# DP32G030 register map
File version: 1.0
CPU: CM0 r0p0, little endian, no MPU, no FPU, 4 interrupt priority bits
Registers are 32-bit, read-write, reset 0x0 unless marked. A register's access mark holds for its fields unless they carry their own. Offsets are from the block's base; [hi:lo] are bit positions.

## IIC0 — IIC0 unit
Base 0x400B9000
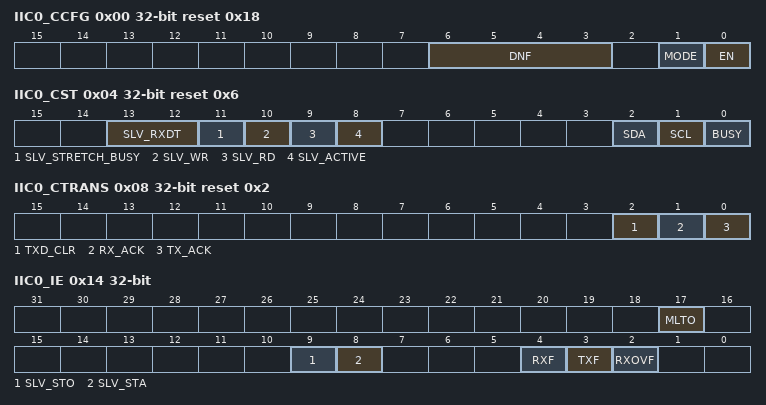
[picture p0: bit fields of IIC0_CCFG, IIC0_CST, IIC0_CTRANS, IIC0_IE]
0x00 IIC0_CCFG reset 0x18 — General Configuration Register
  [6:3] DNF — Receive SDA, SCL Digital Noise Filter 0000: Filter not enabled 0001: Filter enable and filter capacity up to 1 system clock ...... 1111: Filter enable and filter capacity up to 15 system clocks
  [1] MODE — Mode Control 0: slave mode 1: master mode
  [0] EN — IIC Bus Enable 0: not enabled 1: Enabling
0x04 IIC0_CST ro reset 0x6 — General Status Register
  [13:12] SLV_RXDT — The type of data received by the Slave. Valid only in Slave mode. 00: RXDATA is empty. 01: The address is received. 10: Data is received. 11: Master code is received. valid only when MCDE=1.
  [11] SLV_STRETCH_BUSY — Slave clock stretching busy state. Valid only in slave mode. 0: Without clock stretching. 1: With clock stretching.
  [10] SLV_WR — Slave write status. Valid only in slave mode. 1: Valid after the slave receives a write request from the master. 0: The slave is cleared automatically after receiving a read request from the master or STOP.
  [9] SLV_RD — Slave read state. Valid only in slave mode. 1: Valid after the slave receives a read request from the master. 0: The slave is cleared automatically after receiving a write request from the master or STOP.
  [8] SLV_ACTIVE — Slave active state. Valid only in slave mode. 0: slave device is inactive 1: The slave device is active. This bit is active after a successful address match; it is automatically cleared after receiving a STOP, or an unsuccessful address match after Start_repeat.
  [2] SDA — IIC SDA Status. Not affected by IIC bus enable 0: IIC SDA is low 1: IIC SDA is high
  [1] SCL — IIC SCL Status. Not affected by IIC bus enable 0: IIC SCL is low 1: IIC SCL is high
  [0] BUSY — Bus Busy Status. This bit is not controlled by the IIC_CCFG.EN bit and still detects the bus busy state when EN is not enabled 0: Bus not busy 1: Bus busy, IIC bus active from START to STOP
0x08 IIC0_CTRANS access per field reset 0x2 — general transfer register
  [2] TXD_CLR wo write-clears — Transmit data register is cleared. Hardware clears it automatically. 0: Not cleared. 1: Clear the IF.TXE bit.
  [1] RX_ACK ro — When acting as a sender, received ACK/NACK. hardware set, IF.TXF is valid to query this bit; received Start_repeat or STOP will set this bit 1. 0: ACK received 1: NACK received
  [0] TX_ACK rw — Sends ACK/NACK when acting as receiver. 0: Sends ACK. 1: Send NACK. Note: In the following cases, ACK/NACK is not determined by this bit: A. The hardware automatically sends an ACK/NACK when the slave receives the address. B. slave MCDE is valid, hardware automatically returns NACK when master code is received. C. The hardware automatically sends a NACK when the slave receives an overflow.
0x0C IIC0_RXDATA ro — Receive Data Register
  [7:0] RXDATA — Receive data register.IF.RXNE is 1, indicating that valid data exists in this register. Note: This register is updated at the moment of completion of data reception (not including ACK/NACK transmission). See the RXF bit description for slave receive address byte conditions.
0x10 IIC0_TXDATA — send data register
  [7:0] TXDATA — Transmit Data Register.IF.TXE is 0, indicating that there is data to be sent in this register.
0x14 IIC0_IE — interrupt enable register
  [17] MLTO — Master SCL LOW Timeout interrupt enable. 0: Not enabled. 1: Enable.
  [9] SLV_STO — Slave detects STOP interrupt enable. 0: Not enabled. 1: Enable.
  [8] SLV_STA — Slave detects START interrupt enable. 0: Not enabled. 1: Enable.
  [4] RXF — End of receive data interrupt enable. 0: Not enabled. 1: Enable.
  [3] TXF — End-of-send data interrupt enable. 0: Not enabled. 1: Enable.
  [2] RXOVF — Receive data register overflow interrupt enable. 0: Not enabled. 1: Enable.
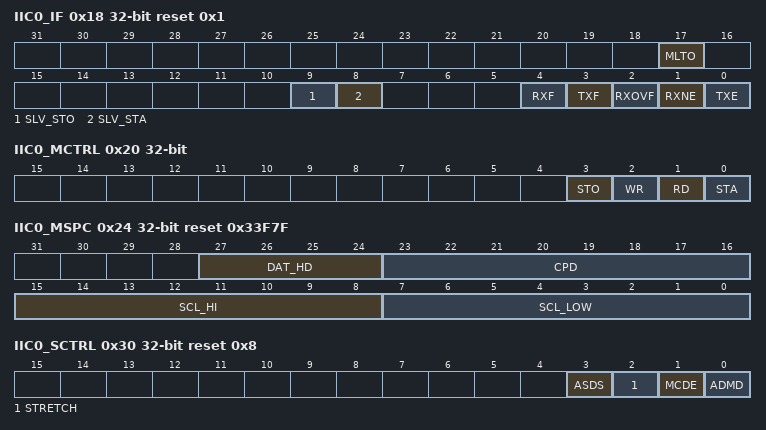
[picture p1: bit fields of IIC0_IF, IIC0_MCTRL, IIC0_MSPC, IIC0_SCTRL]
0x18 IIC0_IF access per field reset 0x1 — Interrupt Flag Register
  [17] MLTO rw write-1-clears — Master SCL LOW timeout. Write 1 clear. Valid only in master mode. 0: No timeout. 1: Timeout. the SCL LOW time exceeds 1024 SCL LOW times set by the MSPC registers.
  [9] SLV_STO rw write-1-clears — Slave detected STOP.write1 clear. Valid only in slave mode. 0: slave did not detect STOP. 1: slave detected STOP.
  [8] SLV_STA rw write-1-clears — Slave detects START. write 1 clear. Valid only in slave mode. 0: slave does not detect START. 1: slave detects START.
  [4] RXF rw write-1-clears — End of reception. Write 1 Clear, contains ACK/NACK time. 0: Receiving is not finished. 1: End of reception. Note: The slave receives the situation description: 1. In 7-bit address mode of Slave device, the slave address byte (inclusive) is used as the address of the slave device. (R/W bits) Receipt is complete and this interrupt is generated if the address matches. 2. In 10-bit address mode of Slave device, when the second byte of slave address (ADDR[7:0]) is received, this interrupt will be generated if the 10-bit address matches; the first byte of the slave address following repeat START, this interrupt will be generated if the address of 8 or9 bits matches; the first byte following repeat START will not generate this interrupt even if ADDR[9:8] matches after the first byte of the slave address has been received. After the first byte following START is received, even if ADDR[9:8] matches, this interrupt will not be generated. 3. Slave mode, SCTRL.MCDE=1, receive master code This interrupt is generated when
  [3] TXF rw write-1-clears — End of transmission. Write 1 Clear, contains ACK/NACK time. 0: Sending is not finished, or not sent. 1: End of sending.
  [2] RXOVF rw write-1-clears — Receive data register overflow. Software Write 1 Clear.(Updated point in time, not including ACK/NACK transmissions) 0: No overflow. 1: When RXDATA is non-null and a new byte is received, an overflow occurs. When the overflow occurs, the new data is lost. Note: For slave mode, if the STRETCH bit is valid, when the receive data register is non-empty and a new byte is received, the slave device pulls down the SCL signal until the old data in RXDATA is read away, and then stores the new data in RXDATA, this case will not generate an overflow.
  [1] RXNE ro — The receive data register is not empty. 0: Receive data register empty, no unread receive data exists. 1: The receive data register is not empty and there is unread receive data. Note: This bit is updated at the moment when the data is finished being received (excluding the ACK/NACK transmit time). If the old data is not read in time when the reception of new data is completed, it is handled in the following cases: Master mode: New data is lost. RXOVF bit is set at the same time. Slave mode: A. STRETCH=0: New data is lost. Simultaneously set IF. RXOVF bit, the hardware automatically sends a NACK. B. STRETCH=1: Normal return to ACK, then before the master sends the next byte, slave holds SCL low until the old data is read away and then updates the new data into the RXDATA register. Finally release SCL.
  [0] TXE ro — Send data register empty. 0: The transmit data register is non-empty and writing the TXDATA register is not allowed. 1: The transmit data register is empty, allowing the TXDATA register to be written. Note: This bit is updated to 1 after the transmit data is read away by the hardware at the moment the transmit data is started (when IF.TXF is still 0). Writing new data to the TXDATA register clears this bit.
0x20 IIC0_MCTRL wo — Host Mode Control Register
  [3] STO write-clears — Write 1 to generate STOP, which is automatically cleared upon completion.
  [2] WR write-clears — Write 1 to send the data in TXDATA, which is automatically cleared when finished (including ACK/NACK time). Before writing 1 to this bit, TXDATA must not be empty. Otherwise, this bit cannot be set. Note: The WR and RD bits cannot be written to 1 at the same time.
  [1] RD write-clears — Write 1, receive data into RXDATA, and when finished (with ACK/NACK), write 1, receive data into RXDATA. time) is automatically cleared.
  [0] STA write-clears — Write 1 to generate START, which is automatically cleared upon completion. Note: Allow STA and WR to be set at the same time to prioritize sending START.
0x24 IIC0_MSPC reset 0x33F7F — Timing Configuration Register
  [27:24] DAT_HD — SDA Data Hold Time Configuration. (Valid for Master and Slave) For master: tHD;DAT = (DAT_HD + 4) * Tpclk For slave: tHD;DAT = (DAT_HD + DNF + 6) * Tpclk Note: If the application environment is harsh, it should be noted that a burr that occurs during the SDA data hold has the potential to cause the SDA to change along the time that advances the width of the burr (if there is no burr on the SCL at this time, an unanticipated STA, STOP will occur on the bus). In this case, DAT_HD should be set so that tHD;DAT is greater than the maximum burr width.
  [23:16] CPD — Clock prescaling, see SCL_HI and SCL_LOW descriptions for details.(Only for (Master mode active)
  [15:8] SCL_HI — SCL Clock High Time Configuration. (available only in Master mode) tHIGH=( (SCL_HI+1) * (CPD+1) + DNF + 6) * Tpclk
  [7:0] SCL_LOW — SCL Clock Low Time Configuration. (Valid for Master mode; in slave mode, this register needs to be configured if the STRETCH function is enabled and SCTRL.ASDS is configured to 0.) After slave writes TXDATA, delay the time set in this register before releasing SCL.) tLOW=( (SCL_LOW+1) * (CPD+1) + DAT_HD + 5) * Tpclk The period of SCL is tHIGH+tLOW. The recommended ratio of tHIGH to tLOW is 1:2.
0x30 IIC0_SCTRL reset 0x8 — Slave Mode Control Register
  [3] ASDS — Adaptive Data Setup Time Enable after Stretching. (Adaptive Stretching Data Setup) 0: Adaptive is not enabled. Set by MSPC. 1: Adaptive Enable. Automatically detects SCL when receiving master address Low level time as data build-up time after stretching. Note: Slave-transmitter, when the STRETCH register is set to valid and stretching occurs, the salve will continue to pull down the SCL for a period of time after the new data is ready to ensure that the SDA line meets the data setup time requirement.
  [2] STRETCH — Clock stretching enable control. 0: Clock stretching is not enabled. 1: Clock stretching is enabled. Note:(When the slave acts as a receiver, when new data is received but the old data is not read in time (IF.RXNE=1): CTRANS. STRETCH_BUSY becomes effective, and after returning to ACK, hold SCL at low level until the old data is read, then update the new data to RXDATA, and at the same time, STRETCH_BUSY becomes ineffective, and then release SCL to start the next data reception. BUSY becomes invalid, then release SCL to start the next data reception. When the slave acts as a transmitter, when the transmission is finished (IF. TXF=1, including the time of receiving ACK/NACK),but the new data is not ready (TXE=1): CTRANS.STRETCH_BUSY becomes active, holds SCL at low level until the new data is ready, and after delaying the SCL_LOW time. STRETCH_BUSY becomes invalid, and then release SCL to start sending new data).
  [1] MCDE — Master Code Detect Enable. 0: Master code is not detected. 1: Master code is detected. When this bit is valid, slave detects master code after START and generates IF.RXF interrupt and hardware sets CST. SLV_RXDT to 11. software should make sure that slave address setting does not conflict with master code.
  [0] ADMD — slave Address mode control. 0: 7-bit address mode 1: 10-bit address mode
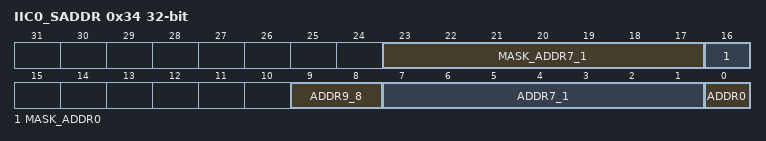
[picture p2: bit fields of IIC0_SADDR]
0x34 IIC0_SADDR — Slave Mode Address Register
  [23:17] MASK_ADDR7_1 — Slave Corresponding Address Bit Mask. 0: No masking. 1: The mask corresponds to the bit address. After masking, the masked address bits are ignored when hardware matches the slave address. For 10-bit address mode, RXDATA only holds ADDR[7:0], so masking of ADDR[9:8] is not supported.
  [16] MASK_ADDR0 — Slave Corresponding Address Bit Mask.
  [9:8] ADDR9_8 — 7-bit address mode: don't care 10-bit address mode: address bit9~bit8
  [7:1] ADDR7_1 — Address bit7~bit1
  [0] ADDR0 — 7-bit address mode: don't care 10-bit address mode: address bit0

## IIC1 — IIC1 unit
Base 0x400B9800
Registers as IIC0 (with IIC0 read as IIC1).
